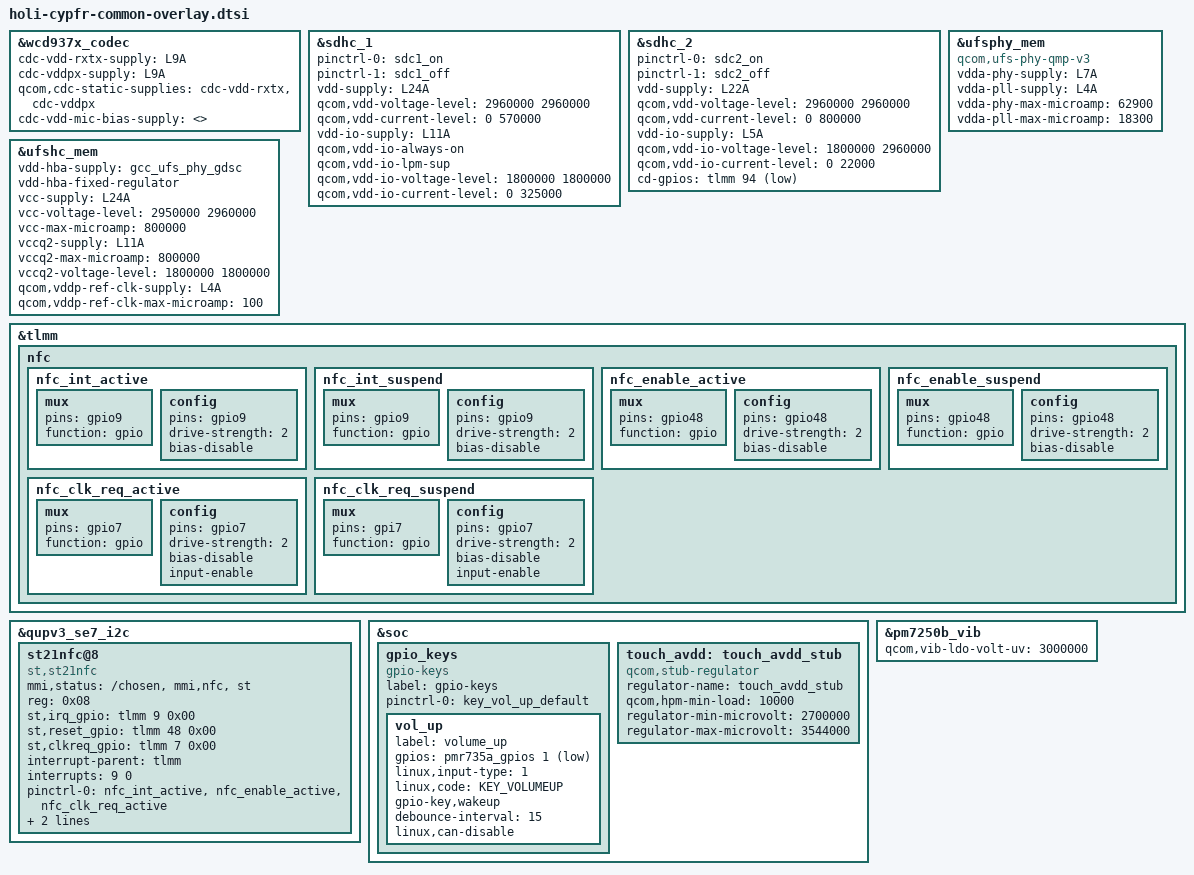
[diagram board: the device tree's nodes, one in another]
/* Copyright (c) 2021, The Linux Foundation. All rights reserved.
 *
 * This program is free software; you can redistribute it and/or modify
 * it under the terms of the GNU General Public License version 2 and
 * only version 2 as published by the Free Software Foundation.
 *
 * This program is distributed in the hope that it will be useful,
 * but WITHOUT ANY WARRANTY; without even the implied warranty of
 * MERCHANTABILITY or FITNESS FOR A PARTICULAR PURPOSE.  See the
 * GNU General Public License for more details.
 */
#include "holi-pm6125-moto-common-overlay.dtsi"

#include "holi-audio-wcd9370-aw882xx-overlay.dtsi"
#include <dt-bindings/gpio/gpio.h>
#include <dt-bindings/input/linux-event-codes.h>
#include "cypfq-fps-overlay.dtsi"
#include "holi-pmic-overlay-pm6125.dtsi"
#include "holi-thermal-overlay-pm6125.dtsi"
#include "display/holi-sde-display-mtp-pm6125.dtsi"
#include "camera/holi-camera-pm6125-overlay.dtsi"

&wcd937x_codec {
	cdc-vdd-rxtx-supply = <&L9A>;
	cdc-vddpx-supply = <&L9A>;
	qcom,cdc-static-supplies = "cdc-vdd-rxtx",
				   "cdc-vddpx";
	/*
	 * Overriding cdc-vdd-mic-bias-supply to dummy value
	 * to avoid compilation errors as BOB is not definied
	 * for pm6125
	 */
	cdc-vdd-mic-bias-supply = <>;
};

/* Dummy LDO reference */
&sdhc_1 {
	status = "ok";

	pinctrl-names = "default", "sleep";
	pinctrl-0 = <&sdc1_on>;
	pinctrl-1 = <&sdc1_off>;

	vdd-supply = <&L24A>;
	qcom,vdd-voltage-level = <2960000 2960000>;
	qcom,vdd-current-level = <0 570000>;

	vdd-io-supply = <&L11A>;
	qcom,vdd-io-always-on;
	qcom,vdd-io-lpm-sup;
	qcom,vdd-io-voltage-level = <1800000 1800000>;
	qcom,vdd-io-current-level = <0 325000>;
};

&sdhc_2 {
	status = "ok";

	pinctrl-names = "default", "sleep";
	pinctrl-0 = <&sdc2_on>;
	pinctrl-1 = <&sdc2_off>;

	vdd-supply = <&L22A>;
	qcom,vdd-voltage-level = <2960000 2960000>;
	qcom,vdd-current-level = <0 800000>;

	vdd-io-supply = <&L5A>;
	qcom,vdd-io-voltage-level = <1800000 2960000>;
	qcom,vdd-io-current-level = <0 22000>;

	cd-gpios = <&tlmm 94 GPIO_ACTIVE_LOW>;
};

&ufsphy_mem {
		compatible = "qcom,ufs-phy-qmp-v3";

		vdda-phy-supply = <&L7A>;
		vdda-pll-supply = <&L4A>;
		vdda-phy-max-microamp = <62900>;
		vdda-pll-max-microamp = <18300>;

		status = "ok";
};

&ufshc_mem {
		vdd-hba-supply = <&gcc_ufs_phy_gdsc>;
		vdd-hba-fixed-regulator;

		vcc-supply = <&L24A>;
		vcc-voltage-level = <2950000 2960000>;
		vcc-max-microamp = <800000>;

		vccq2-supply = <&L11A>;
		vccq2-max-microamp = <800000>;
		vccq2-voltage-level = <1800000 1800000>;

		qcom,vddp-ref-clk-supply = <&L4A>;
		qcom,vddp-ref-clk-max-microamp = <100>;

		status = "ok";
};

&tlmm {
	nfc {
		nfc_int_active: nfc_int_active {
			/* active state */
			mux {
				/* GPIO 9: NFC Read Interrupt */
				pins = "gpio9";
				function = "gpio";
			};

			config {
				pins = "gpio9";
				drive-strength = <2>; /* 2 MA */
				bias-disable;
			};
		};

		nfc_int_suspend: nfc_int_suspend {
			/* sleep state */
			mux {
				/* GPIO 9: NFC Read Interrupt */
				pins = "gpio9";
				function = "gpio";
			};

			config {
				pins = "gpio9";
				drive-strength = <2>; /* 2 MA */
				bias-disable;
			};
		};

		nfc_enable_active: nfc_enable_active {
			mux {
				/* 48: Enable, 8: Firmware*/
				pins = "gpio48";
				function = "gpio";
			};

			config {
				pins = "gpio48";
				drive-strength = <2>; /* 2 MA */
				bias-disable;
			};
		};

		nfc_enable_suspend: nfc_enable_suspend {
			mux {
				/* 48: Enable, 8: Firmware */
				pins = "gpio48";
				function = "gpio";
			};

			config {
				pins = "gpio48";
				drive-strength = <2>; /* 2 MA */
				bias-disable;
			};
		};


		nfc_clk_req_active: nfc_clk_req_active {
			/* active state */
			mux {
				/* GPIO 7: NFC CLK Req*/
				pins = "gpio7";
				function = "gpio";
			};

			config {
				pins = "gpio7";
				drive-strength = <2>; /* 2 MA */
				bias-disable;
				input-enable;
			};
		};

		nfc_clk_req_suspend: nfc_clk_req_suspend {
			/* sleep state */
			mux {
				/* GPIO 7: NFC CLK Req */
				pins = "gpi7";
				function = "gpio";
			};

			config {
				pins = "gpio7";
				drive-strength = <2>; /* 2 MA */
				bias-disable;
				input-enable;
			};
		};
	};
};

&qupv3_se7_i2c {
	status = "ok";
	#address-cells = <1>;
	#size-cells = <0>;
	st21nfc@8 {
		compatible = "st,st21nfc";
		mmi,status = "/chosen", "mmi,nfc", "st";
		status = "ok";
		reg = <0x08>;
		st,irq_gpio = <&tlmm 9 0x00>;
		st,reset_gpio = <&tlmm 48 0x00>;
		st,clkreq_gpio = <&tlmm 7 0x00>;
		interrupt-parent = <&tlmm>;
		interrupts = <9 0>;
		interrupt-names = "nfc_irq";
		pinctrl-names = "nfc_active", "nfc_suspend";
		pinctrl-0 = <&nfc_int_active &nfc_enable_active
				&nfc_clk_req_active>;
		pinctrl-1 = <&nfc_int_suspend &nfc_enable_suspend
				&nfc_clk_req_suspend>;
	};
};

&soc {
	gpio_keys {
		compatible = "gpio-keys";
		label = "gpio-keys";

		pinctrl-names = "default";
		pinctrl-0 = <&key_vol_up_default>;

		vol_up {
			label = "volume_up";
			gpios = <&pmr735a_gpios 1 GPIO_ACTIVE_LOW>;
			linux,input-type = <1>;
			linux,code = <KEY_VOLUMEUP>;
			gpio-key,wakeup;
			debounce-interval = <15>;
			linux,can-disable;
		};
	};
};

&soc {
	touch_avdd: touch_avdd_stub {
		/*
		 * Touch eLDO controlled by gpio#53 is always ON.
		 * Using dummy regulator.
		 */
		compatible = "qcom,stub-regulator";
		regulator-name = "touch_avdd_stub";
		qcom,hpm-min-load = <10000>;
		regulator-min-microvolt = <2700000>;
		regulator-max-microvolt = <3544000>;
	};
};

&pm7250b_vib {
	qcom,vib-ldo-volt-uv = <3000000>;
};



#include "camera/holi-camera-sensor-pm6125-mtp.dtsi"
